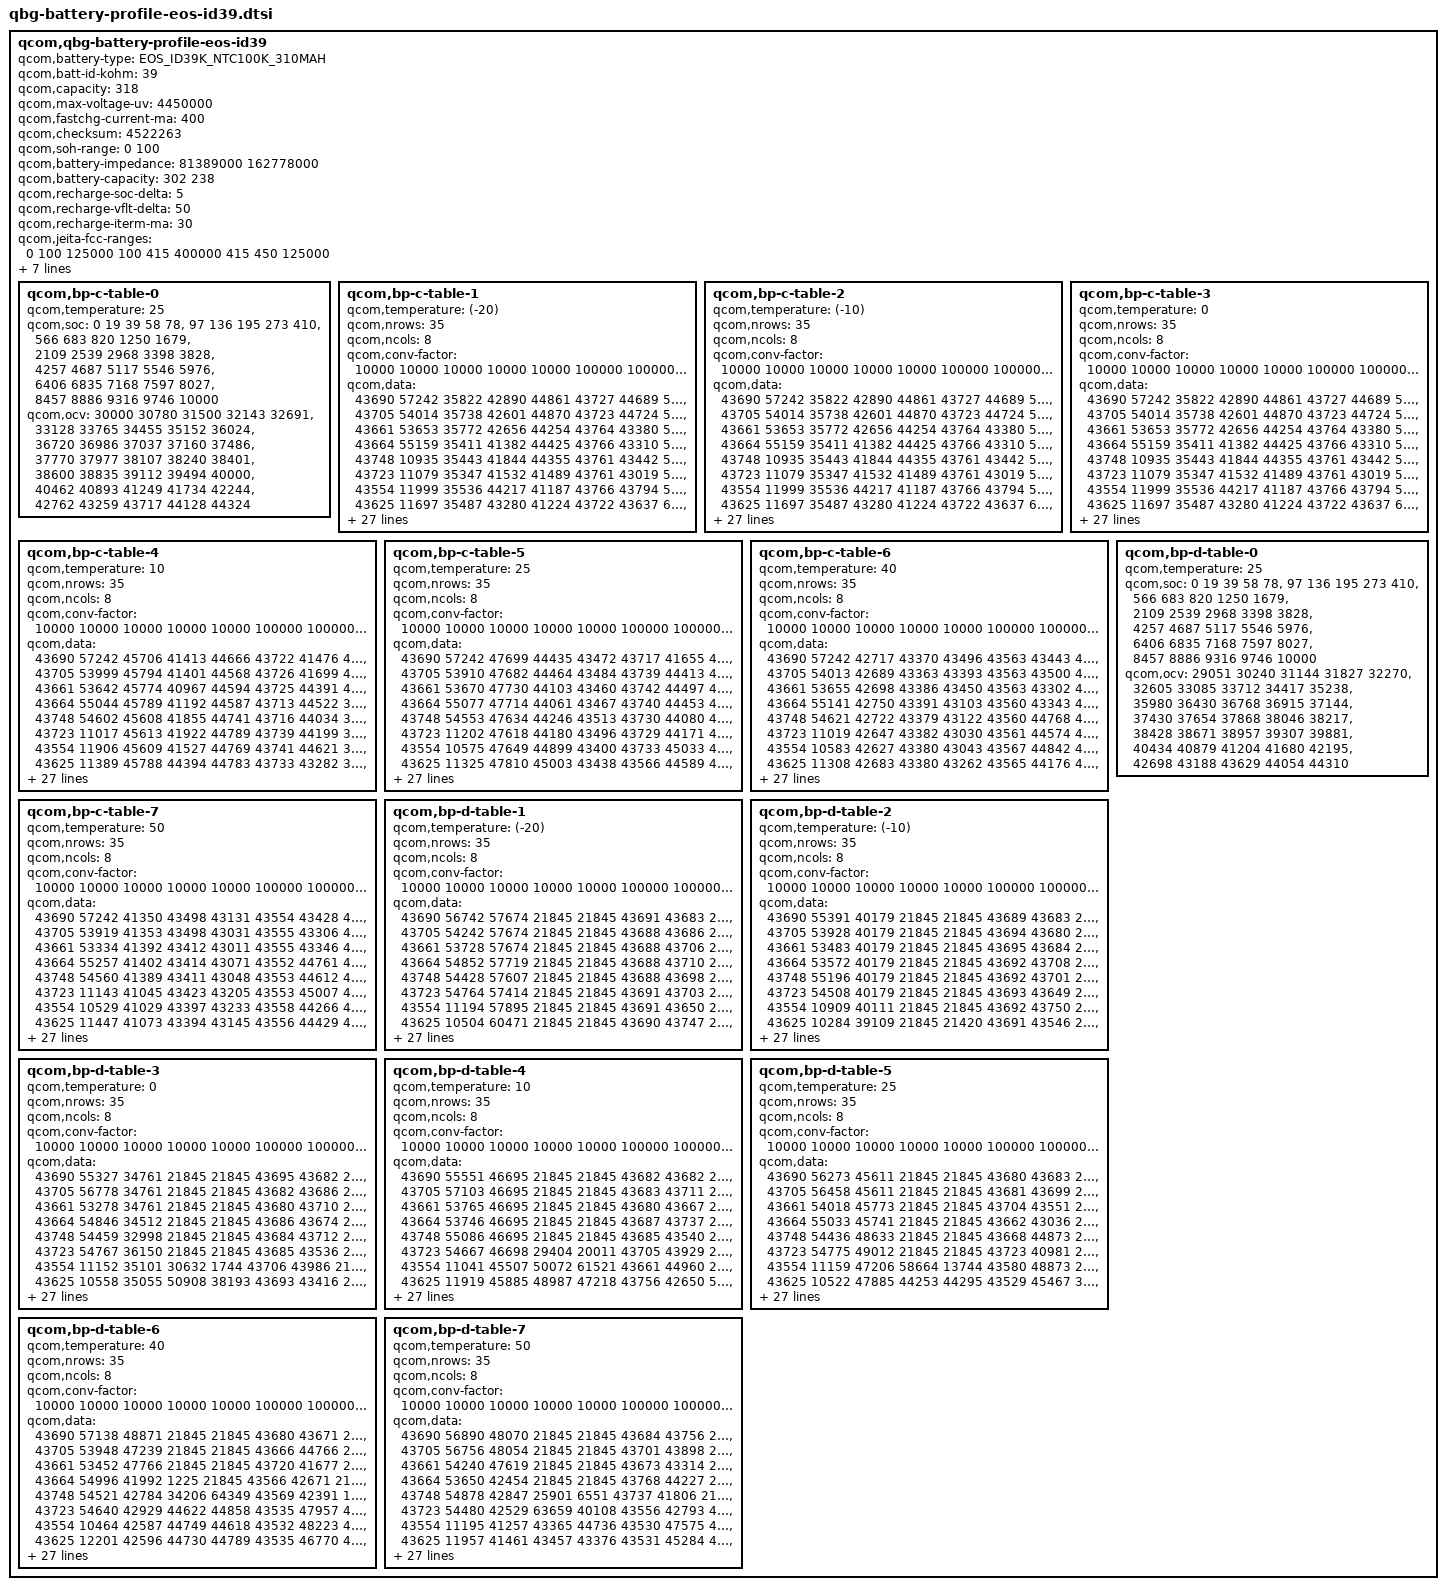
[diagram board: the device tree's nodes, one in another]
// SPDX-License-Identifier: GPL-2.0

/*QBG Profiling Rev. 2.7*/

qcom,qbg-battery-profile-eos-id39 {
	qcom,battery-type = "EOS_ID39K_NTC100K_310MAH";
	qcom,batt-id-kohm = <39>;
	qcom,capacity = <318>;
	qcom,max-voltage-uv = <4450000>;
	qcom,fastchg-current-ma = <400>;
	qcom,checksum = <4522263>; /*@5, 0.005V, 4% */
	qcom,soh-range = <0 100>;
	/*Nominal_Impedance in 10nohm @ SOC 50% 25C* 0:fresh cell, 1: aged cell */
	qcom,battery-impedance = <81389000 162778000>;
	/*Nominal_Capacity in mAh. 0: fresh cell, 1:aged cell*/
	qcom,battery-capacity = <302 238>;
	/*SOC delta (in percent) dropped from EOC SOC to enable recharge*/
	qcom,recharge-soc-delta =<5>;
	/*vfloat delta (in mV) dropped from regular vfloat in recharge*/
	qcom,recharge-vflt-delta =<50>;
	/*termination current (in mA) in recharge*/
	qcom,recharge-iterm-ma = <30>;
	qcom,jeita-fcc-ranges = <0  100 125000
				100 415 400000
				415 450 125000>;

	qcom,jeita-fv-ranges = <0   100 4450000
				100 415 4450000
				415 450 4450000>;

	/* COOL = 10 DegC, WARM = 41 DegC */
	qcom,jeita-soft-thresholds = <0x2b8a 0x14de>;
	/* COLD = 0 DegC, HOT = 45 DegC */
	qcom,jeita-hard-thresholds = <0x3257 0x128c>;
	/* COOL = 12 DegC, WARM = 39 DegC*/
	qcom,jeita-soft-hys-thresholds = <0x2a0b 0x161b>;
	qcom,jeita-soft-fcc-ua = <125000 125000>;
	qcom,jeita-soft-fv-uv = <4450000 4450000>;

	qcom,bp-c-table-0 {
		qcom,temperature = <25>;
		qcom,soc = <    0    19    39    58    78>,
			<   97   136   195   273   410>,
			<  566   683   820  1250  1679>,
			< 2109  2539  2968  3398  3828>,
			< 4257  4687  5117  5546  5976>,
			< 6406  6835  7168  7597  8027>,
			< 8457  8886  9316  9746 10000>;
		qcom,ocv = <30000 30780 31500 32143 32691>,
			<33128 33765 34455 35152 36024>,
			<36720 36986 37037 37160 37486>,
			<37770 37977 38107 38240 38401>,
			<38600 38835 39112 39494 40000>,
			<40462 40893 41249 41734 42244>,
			<42762 43259 43717 44128 44324>;
	};
	qcom,bp-c-table-1 {
		qcom,temperature = <(-20)>;
		qcom,nrows = <35>;
		qcom,ncols = <8>;
		qcom,conv-factor = <10000 10000 10000 10000 10000 100000 100000 10000>;
		qcom,data = <43690 57242 35822 42890 44861 43727 44689 58634>,
			<43705 54014 35738 42601 44870 43723 44724 58378>,
			<43661 53653 35772 42656 44254 43764 43380 59199>,
			<43664 55159 35411 41382 44425 43766 43310 58924>,
			<43748 10935 35443 41844 44355 43761 43442 57820>,
			<43723 11079 35347 41532 41489 43761 43019 57542>,
			<43554 11999 35536 44217 41187 43766 43794 58068>,
			<43625 11697 35487 43280 41224 43722 43637 60655>,
			<43963  9063 46445 43371 41451 43713 43593 60944>,
			<43824 10124 35514 44161 41677 43563 43804 59827>,
			<43164  9597 46437 41588 45038 43553 43464 59567>,
			<43009 14965 46544 44691 41929 43735 43900 59904>,
			<43422 15283 46383 44207 41647 43567 43198 59920>,
			<44616 15112 46550 42720 44909 43729 44228 59762>,
			<44069 14400 46528 42190 44415 43736 44057 60655>,
			<41623 16034 46385 42374 41859 43737 44444 60827>,
			<41793 15949 46531 47790 41927 43739 44484 60830>,
			<41266 16381 46522 47820 41838 43717 44446 60848>,
			<42988 16235 46198 47724 41125 43719 44061 60906>,
			<42078 15509 46147 48035 41005 43719 44890 60700>,
			<47627 15487 46525 48014 41277 43718 45029 57910>,
			<47333 15825 46161 48006 42944 43713 44952 57525>,
			<47447 12937 46163 47280 42461 43715 44436 58976>,
			<48896 13096 46186 47488 42629 43712 41840 57481>,
			<48626 12772 46296 47945 40962 43712 44148 60648>,
			<45996 14262 46281 47714 41800 43712 44722 61140>,
			<45081 13419 46122 48115 41863 43714 44798 61154>,
			<46762 13663 46292 47983 41787 43725 44692 61425>,
			<46855  2821 46129 47492 41564 43739 44790 60450>,
			<46577  2515 46142 47387 41776 43718 44682 58004>,
			<35747  4069 46127 48800 42694 43723 43471 57667>,
			<34844  3475 46093 48721 47666 43722 43117 63935>,
			<36558   904 46570 47454 48342 43727 43159 61470>,
			<36024   127 46588 47283 46409 43714 43893 52995>,
			<36282   339 46130 44517 47008 43593 43541 61736>;
	};
	qcom,bp-c-table-2 {
		qcom,temperature = <(-10)>;
		qcom,nrows = <35>;
		qcom,ncols = <8>;
		qcom,conv-factor = <10000 10000 10000 10000 10000 100000 100000 10000>;
		qcom,data = <43690 57242 35822 42890 44861 43727 44689 58634>,
			<43705 54014 35738 42601 44870 43723 44724 58378>,
			<43661 53653 35772 42656 44254 43764 43380 59199>,
			<43664 55159 35411 41382 44425 43766 43310 58924>,
			<43748 10935 35443 41844 44355 43761 43442 57820>,
			<43723 11079 35347 41532 41489 43761 43019 57542>,
			<43554 11999 35536 44217 41187 43766 43794 58068>,
			<43625 11697 35487 43280 41224 43722 43637 60655>,
			<43963  9063 46445 43371 41451 43713 43593 60944>,
			<43824 10124 35514 44161 41677 43563 43804 59827>,
			<43164  9597 46437 41588 45038 43553 43464 59567>,
			<43009 14965 46544 44691 41929 43735 43900 59904>,
			<43422 15283 46383 44207 41647 43567 43198 59920>,
			<44616 15112 46550 42720 44909 43729 44228 59762>,
			<44069 14400 46528 42190 44415 43736 44057 60655>,
			<41623 16034 46385 42374 41859 43737 44444 60827>,
			<41793 15949 46531 47790 41927 43739 44484 60830>,
			<41266 16381 46522 47820 41838 43717 44446 60848>,
			<42988 16235 46198 47724 41125 43719 44061 60906>,
			<42078 15509 46147 48035 41005 43719 44890 60700>,
			<47627 15487 46525 48014 41277 43718 45029 57910>,
			<47333 15825 46161 48006 42944 43713 44952 57525>,
			<47447 12937 46163 47280 42461 43715 44436 58976>,
			<48896 13096 46186 47488 42629 43712 41840 57481>,
			<48626 12772 46296 47945 40962 43712 44148 60648>,
			<45996 14262 46281 47714 41800 43712 44722 61140>,
			<45081 13419 46122 48115 41863 43714 44798 61154>,
			<46762 13663 46292 47983 41787 43725 44692 61425>,
			<46855  2821 46129 47492 41564 43739 44790 60450>,
			<46577  2515 46142 47387 41776 43718 44682 58004>,
			<35747  4069 46127 48800 42694 43723 43471 57667>,
			<34844  3475 46093 48721 47666 43722 43117 63935>,
			<36558   904 46570 47454 48342 43727 43159 61470>,
			<36024   127 46588 47283 46409 43714 43893 52995>,
			<36282   339 46130 44517 47008 43593 43541 61736>;
	};
	qcom,bp-c-table-3 {
		qcom,temperature = <0>;
		qcom,nrows = <35>;
		qcom,ncols = <8>;
		qcom,conv-factor = <10000 10000 10000 10000 10000 100000 100000 10000>;
		qcom,data = <43690 57242 35822 42890 44861 43727 44689 58634>,
			<43705 54014 35738 42601 44870 43723 44724 58378>,
			<43661 53653 35772 42656 44254 43764 43380 59199>,
			<43664 55159 35411 41382 44425 43766 43310 58924>,
			<43748 10935 35443 41844 44355 43761 43442 57820>,
			<43723 11079 35347 41532 41489 43761 43019 57542>,
			<43554 11999 35536 44217 41187 43766 43794 58068>,
			<43625 11697 35487 43280 41224 43722 43637 60655>,
			<43963  9063 46445 43371 41451 43713 43593 60944>,
			<43824 10124 35514 44161 41677 43563 43804 59827>,
			<43164  9597 46437 41588 45038 43553 43464 59567>,
			<43009 14965 46544 44691 41929 43735 43900 59904>,
			<43422 15283 46383 44207 41647 43567 43198 59920>,
			<44616 15112 46550 42720 44909 43729 44228 59762>,
			<44069 14400 46528 42190 44415 43736 44057 60655>,
			<41623 16034 46385 42374 41859 43737 44444 60827>,
			<41793 15949 46531 47790 41927 43739 44484 60830>,
			<41266 16381 46522 47820 41838 43717 44446 60848>,
			<42988 16235 46198 47724 41125 43719 44061 60906>,
			<42078 15509 46147 48035 41005 43719 44890 60700>,
			<47627 15487 46525 48014 41277 43718 45029 57910>,
			<47333 15825 46161 48006 42944 43713 44952 57525>,
			<47447 12937 46163 47280 42461 43715 44436 58976>,
			<48896 13096 46186 47488 42629 43712 41840 57481>,
			<48626 12772 46296 47945 40962 43712 44148 60648>,
			<45996 14262 46281 47714 41800 43712 44722 61140>,
			<45081 13419 46122 48115 41863 43714 44798 61154>,
			<46762 13663 46292 47983 41787 43725 44692 61425>,
			<46855  2821 46129 47492 41564 43739 44790 60450>,
			<46577  2515 46142 47387 41776 43718 44682 58004>,
			<35747  4069 46127 48800 42694 43723 43471 57667>,
			<34844  3475 46093 48721 47666 43722 43117 63935>,
			<36558   904 46570 47454 48342 43727 43159 61470>,
			<36024   127 46588 47283 46409 43714 43893 52995>,
			<36282   339 46130 44517 47008 43593 43541 61736>;
	};
	qcom,bp-c-table-4 {
		qcom,temperature = <10>;
		qcom,nrows = <35>;
		qcom,ncols = <8>;
		qcom,conv-factor = <10000 10000 10000 10000 10000 100000 100000 10000>;
		qcom,data = <43690 57242 45706 41413 44666 43722 41476 40809>,
			<43705 53999 45794 41401 44568 43726 41699 40533>,
			<43661 53642 45774 40967 44594 43725 44391 40600>,
			<43664 55044 45789 41192 44587 43713 44522 39370>,
			<43748 54602 45608 41855 44741 43716 44034 38948>,
			<43723 11017 45613 41922 44789 43739 44199 39787>,
			<43554 11906 45609 41527 44769 43741 44621 39650>,
			<43625 11389 45788 44394 44783 43733 43282 33805>,
			<43963  9018 45793 44435 44766 43565 43407 34612>,
			<43824  9817 48486 44093 44670 43578 43038 34517>,
			<43164  9479 48436 44080 44604 43579 43396 33046>,
			<43009 14861 48446 44115 43305 43554 44748 32770>,
			<43422 14922 48430 44519 43516 43554 44989 32812>,
			<44616 15304 48581 41489 44819 43561 44996 34603>,
			<44069 14348 48610 41825 44462 43732 44886 33881>,
			<41623 14690 48572 41095 44396 43733 44232 34087>,
			<41793 15886 48211 41087 44303 43728 44528 34094>,
			<41266 16312 48210 41404 44338 43730 44533 34276>,
			<42988 16168 48254 41436 44346 43743 44477 34289>,
			<42078 15527 48159 42658 44288 43742 44235 34051>,
			<47627 15380 48141 41306 41510 43743 44564 39679>,
			<47333 15674 48178 41404 41385 43741 43297 39875>,
			<47447 13021 48169 40986 42930 43742 43269 38985>,
			<48896 13096 48278 42657 42791 43736 44146 40679>,
			<48626 12642 48304 41315 44048 43554 44633 34374>,
			<45996 14130 48299 42625 44970 43571 44939 33033>,
			<45081 13703 48986 41340 44917 43564 44571 33109>,
			<46762  2756 48960 41425 44469 43736 43358 34404>,
			<46855  2193 48960 41339 44342 43738 43313 34670>,
			<46577  3720 48990 42894 44542 43735 43366 34191>,
			<35747  3257 48267 42881 41570 43738 43509 39816>,
			<34844   675 48365 42170 41256 43713 43072 40917>,
			<36558   841 48375 42124 47799 43719 43218 37205>,
			<36024   312 48375 41239 48268 43564 43891 59941>,
			<36282  1751 48277 44361 45880 43640 44011 60162>;
	};
	qcom,bp-c-table-5 {
		qcom,temperature = <25>;
		qcom,nrows = <35>;
		qcom,ncols = <8>;
		qcom,conv-factor = <10000 10000 10000 10000 10000 100000 100000 10000>;
		qcom,data = <43690 57242 47699 44435 43472 43717 41655 46168>,
			<43705 53910 47682 44464 43484 43739 44413 46138>,
			<43661 53670 47730 44103 43460 43742 44497 46222>,
			<43664 55077 47714 44061 43467 43740 44453 46872>,
			<43748 54553 47634 44246 43513 43730 44080 46997>,
			<43723 11202 47618 44180 43496 43729 44171 46695>,
			<43554 10575 47649 44899 43400 43733 45033 45398>,
			<43625 11325 47810 45003 43438 43566 44589 45443>,
			<43963  9210 47843 45037 43102 43554 44754 45078>,
			<43824  9746 47807 44646 43421 43578 43291 45185>,
			<43164  9690 42320 44772 43325 43572 43449 45925>,
			<43009 15056 42352 43365 43434 43581 44731 45607>,
			<43422 14855 42345 44718 43075 43581 44548 45627>,
			<44616 15234 42258 44638 44860 43575 43308 46766>,
			<44069 14532 42450 45003 44916 43574 44769 46639>,
			<41623 14624 42484 44847 44181 43575 44620 46715>,
			<41793 16115 42473 44907 44882 43577 44221 46600>,
			<41266 15985 42379 44921 45030 43557 44253 45387>,
			<42988 16330 42065 44169 44990 43552 44917 45438>,
			<42078 15531 42111 44130 45054 43567 44970 46652>,
			<47627 15458 41990 44438 44212 43564 43388 46869>,
			<47333 15641 42022 44122 44359 43576 43114 46476>,
			<47447 12898 42176 44919 41142 43582 43042 46405>,
			<48896 12524 42210 44811 41775 43556 43265 46164>,
			<48626 14058 42138 44248 44606 43576 44889 45152>,
			<45996 13476 42120 44076 43451 43536 44980 46066>,
			<45081 13591 42166 44133 43469 43544 44546 45907>,
			<46762  2955 42175 44288 43464 43549 45003 45080>,
			<46855  2476 42174 44464 44985 43574 43357 45387>,
			<46577  4014 42120 44351 44816 43569 43472 47086>,
			<35747  3488 42210 41561 45041 43527 44692 46204>,
			<34844   593 42177 41705 41692 43561 43084 35746>,
			<36558   111 42040 41495 41415 43567 43225 36380>,
			<36024  1738 42037 44995 42317 44013 43974 35969>,
			<36282  1934 42211 44561 41240 43563 43889 35754>;
	};
	qcom,bp-c-table-6 {
		qcom,temperature = <40>;
		qcom,nrows = <35>;
		qcom,ncols = <8>;
		qcom,conv-factor = <10000 10000 10000 10000 10000 100000 100000 10000>;
		qcom,data = <43690 57242 42717 43370 43496 43563 43443 48721>,
			<43705 54013 42689 43363 43393 43563 43500 48740>,
			<43661 53655 42698 43386 43450 43563 43302 48651>,
			<43664 55141 42750 43391 43103 43560 43343 48862>,
			<43748 54621 42722 43379 43122 43560 44768 48866>,
			<43723 11019 42647 43382 43030 43561 44574 48820>,
			<43554 10583 42627 43380 43043 43567 44842 47482>,
			<43625 11308 42683 43380 43262 43565 44176 47580>,
			<43963  9088 41302 43385 43160 43552 44085 47488>,
			<43824  9940 41289 43369 43150 43556 44094 47178>,
			<43164  9613 41339 43298 43242 43570 44842 47114>,
			<43009 14999 41312 43221 43255 43544 44551 47911>,
			<43422 15045 41321 43041 43253 43524 44971 47933>,
			<44616 14921 41244 43418 44551 43527 43085 48688>,
			<44069 14478 41224 43414 44603 43545 43309 48849>,
			<41623 14739 41278 43461 44645 43539 44734 48766>,
			<41793 16057 41260 43410 44654 43525 44700 48674>,
			<41266 15888 41414 43429 43329 43573 44580 47405>,
			<42988 16379 41464 43485 43278 43570 44553 47418>,
			<42078 15528 41360 43332 44706 43583 43364 48832>,
			<47627 15481 41397 44791 44561 43581 43446 48935>,
			<47333 15726 41378 44637 44846 43573 43087 48213>,
			<47447 12870 41048 44682 44521 43544 43234 48431>,
			<48896 12323 41073 43459 44080 43521 43099 48261>,
			<48626 14041 41056 43445 43333 43574 43370 47174>,
			<45996 13462 40981 43112 43511 43574 43132 47955>,
			<45081 13662 40991 43398 43279 43575 43085 47134>,
			<46762  3019 40965 44969 43055 43598 44267 47570>,
			<46855  2552 40964 44697 44788 43526 43320 48856>,
			<46577  4089 40986 45054 44731 43643 44789 48942>,
			<35747  3568 40976 44175 43329 43588 44668 48174>,
			<34844  1007 41061 44194 44959 43641 43390 48441>,
			<36558    85 41079 45043 44337 43551 43082 45956>,
			<36024  1568 41074 43266 44294 44017 43144 48391>,
			<36282  2045 41194 43009 41568 43568 43798 48222>;
	};
	qcom,bp-c-table-7 {
		qcom,temperature = <50>;
		qcom,nrows = <35>;
		qcom,ncols = <8>;
		qcom,conv-factor = <10000 10000 10000 10000 10000 100000 100000 10000>;
		qcom,data = <43690 57242 41350 43498 43131 43554 43428 47155>,
			<43705 53919 41353 43498 43031 43555 43306 47320>,
			<43661 53334 41392 43412 43011 43555 43346 47329>,
			<43664 55257 41402 43414 43071 43552 44761 47247>,
			<43748 54560 41389 43411 43048 43553 44612 47957>,
			<43723 11143 41045 43423 43205 43553 45007 47985>,
			<43554 10529 41029 43397 43233 43558 44266 47923>,
			<43625 11447 41073 43394 43145 43556 44429 48097>,
			<43963  8815 41069 43402 43178 43578 44399 48044>,
			<43824  9911 40989 43444 43851 43583 41717 47723>,
			<43164  9325 40975 43448 43900 43571 41654 47649>,
			<43009  9556 41015 43840 43149 43630 43345 42285>,
			<43422 15005 41011 43865 43191 43541 44617 42287>,
			<44616 14862 41019 43253 44705 43536 43071 47960>,
			<44069 15220 41007 43134 43327 43548 44721 47948>,
			<41623 14423 41171 43071 44709 43537 43269 47265>,
			<41793 14709 41155 43048 44706 43538 43350 47936>,
			<41266 15927 41213 43248 43464 43547 44740 48058>,
			<42988 16366 41198 43049 43429 43534 44689 47732>,
			<42078 16209 41092 43132 43310 43569 43495 47876>,
			<47627 15461 41149 43304 43358 43568 43408 47215>,
			<47333 15712 41132 43265 44640 43530 43015 47476>,
			<47447 12884 41817 43409 44201 43525 43196 48877>,
			<48896 12298 41803 43226 45020 43545 43253 47520>,
			<48626 13866 41848 43242 43512 43525 43476 47808>,
			<45996 13551 41836 43208 43055 43520 43339 42258>,
			<45081  2731 41747 43231 43444 43522 43441 47818>,
			<46762  3038 41755 43064 43316 43533 43129 47709>,
			<46855  2511 41728 43318 43510 43643 44749 47986>,
			<46577  4034 41730 43376 43388 43647 44710 47114>,
			<35747  3533 41729 44798 44699 43594 44691 47405>,
			<34844   999 41759 44762 44641 43621 44721 48841>,
			<36558   431 41747 44689 44074 43630 43443 49001>,
			<36024  1571 41752 43489 45034 43606 43490 47412>,
			<36282  1992 41556 43196 41680 43533 43800 48667>;
	};
	qcom,bp-d-table-0 {
		qcom,temperature = <25>;
		qcom,soc = <    0    19    39    58    78>,
			<   97   136   195   273   410>,
			<  566   683   820  1250  1679>,
			< 2109  2539  2968  3398  3828>,
			< 4257  4687  5117  5546  5976>,
			< 6406  6835  7168  7597  8027>,
			< 8457  8886  9316  9746 10000>;
		qcom,ocv = <29051 30240 31144 31827 32270>,
			<32605 33085 33712 34417 35238>,
			<35980 36430 36768 36915 37144>,
			<37430 37654 37868 38046 38217>,
			<38428 38671 38957 39307 39881>,
			<40434 40879 41204 41680 42195>,
			<42698 43188 43629 44054 44310>;
	};
	qcom,bp-d-table-1 {
		qcom,temperature = <(-20)>;
		qcom,nrows = <35>;
		qcom,ncols = <8>;
		qcom,conv-factor = <10000 10000 10000 10000 10000 100000 100000 10000>;
		qcom,data = <43690 56742 57674 21845 21845 43691 43683 21845>,
			<43705 54242 57674 21845 21845 43688 43686 21845>,
			<43661 53728 57674 21845 21845 43688 43706 21845>,
			<43664 54852 57719 21845 21845 43688 43710 21845>,
			<43748 54428 57607 21845 21845 43688 43698 21845>,
			<43723 54764 57414 21845 21845 43691 43703 21845>,
			<43554 11194 57895 21845 21845 43691 43650 21845>,
			<43625 10504 60471 21845 21845 43690 43747 21845>,
			<43963 11279 61406 21845 32405 43690 43553 21845>,
			<43824  8429 59669 21845 62057 43690 43595 21845>,
			<43164  9822 59908 21845 40702 43690 44015 21845>,
			<43009  9357 38340 21576 33691 43690 43812 21845>,
			<43422  9644 38105 27066 35455 43691 43844 21845>,
			<44616 15068 37224 12515 33504 43691 43186 21845>,
			<44069 15351 37364 53391 33682 43691 43173 21845>,
			<41623 14498 37055 51207 36596 43688 43147 21845>,
			<41793 14384 37389 64167 46880 43688 43233 21845>,
			<41266 14725 39956 59704 45687 43689 43202 21763>,
			<42988 14715 40374 37641 48981 43689 43209 17260>,
			<42078 16087 40798 39780 47462 43689 43249 32110>,
			<47627 16275 40565 33127 47990 43694 43210 25341>,
			<47333 15534 40486 36155 42310 43694 43045  4483>,
			<47447 15476 39267 36412 42837 43695 43079  1297>,
			<48896 15715 39375 35687 42549 43692 43498  4043>,
			<48626 12903 39767 46362 41396 43693 43335 13922>,
			<45996 12463 39769 46482 41953 43693 45014 16203>,
			<45081 12572 39918 46097 41880 43682 44361 15251>,
			<46762 14329 39492 46130 41940 43683 41200  9501>,
			<46855 13589 39505 46182 41075 43683 42170  9286>,
			<46577  2244 39447 46188 42595 43680 47737  9301>,
			<35747  2390 39811 46631 42583 43681 41130  8294>,
			<34844  3230 39487 46990 42566 43686 41827  8611>,
			<36558   537 34138 47096 41325 43684 41871  9174>,
			<36024   465 34198 47098 41903 43706 44333 11862>,
			<36282  2023 34290 46996 41655 43707 44144 10627>;
	};
	qcom,bp-d-table-2 {
		qcom,temperature = <(-10)>;
		qcom,nrows = <35>;
		qcom,ncols = <8>;
		qcom,conv-factor = <10000 10000 10000 10000 10000 100000 100000 10000>;
		qcom,data = <43690 55391 40179 21845 21845 43689 43683 21845>,
			<43705 53928 40179 21845 21845 43694 43680 21845>,
			<43661 53483 40179 21845 21845 43695 43684 21845>,
			<43664 53572 40179 21845 21845 43692 43708 21845>,
			<43748 55196 40179 21845 21845 43692 43701 21845>,
			<43723 54508 40179 21845 21845 43693 43649 21845>,
			<43554 10909 40111 21845 21845 43692 43750 21845>,
			<43625 10284 39109 21845 21420 43691 43546 21845>,
			<43963 12249 39616 21845 64351 43690 44011 21845>,
			<43824  8971 34248  9463 47034 43691 43170 21845>,
			<43164 10146 34710 64152 47789 43691 43429 21845>,
			<43009  9219 34472 37221 42763 43688 43329 19640>,
			<43422  9534 33081 34812 41340 43688 44688 28454>,
			<44616 14975 33603 34734 42100 43689 43321  4128>,
			<44069 15112 33381 33718 47625 43694 43121  2007>,
			<41623 14481 36129 34865 42493 43695 43009 12766>,
			<41793 14357 36314 46813 42512 43692 43117  8231>,
			<41266 14826 36281 48468 41214 43682 43441 54803>,
			<42988 14689 35996 48648 44375 43681 43352 55849>,
			<42078 16066 36687 47893 44067 43684 44643 52370>,
			<47627 16310 36626 42332 44848 43705 44875 62935>,
			<47333 16218 36841 42373 44985 43697 44532 61769>,
			<47447 15443 36418 42102 44612 43662 41592 61586>,
			<48896 13023 36477 42372 44764 43714 47276 61633>,
			<48626 12452 36472 42468 45052 43716 48125 61871>,
			<45996 12652 36466 42360 44216 43742 47992 61753>,
			<45081 13563 36453 47681 41616 43734 47458 62607>,
			<46762 13639 36367 48017 41905 43729 47121 62892>,
			<46855  3067 36595 48111 41908 43717 41057 62611>,
			<46577  2415 36405 48809 41490 43730 48043 51769>,
			<35747  3946 36604 48666 41934 43725 42843 52194>,
			<34844  3357 35158 49145 41745 43764 41426 51452>,
			<36558   783 35093 48935 41592 43769 41949 51985>,
			<36024   379 35125 48930 44210 43756 44411 62528>,
			<36282  2023 35085 49148 44624 43668 44425 62999>;
	};
	qcom,bp-d-table-3 {
		qcom,temperature = <0>;
		qcom,nrows = <35>;
		qcom,ncols = <8>;
		qcom,conv-factor = <10000 10000 10000 10000 10000 100000 100000 10000>;
		qcom,data = <43690 55327 34761 21845 21845 43695 43682 21845>,
			<43705 56778 34761 21845 21845 43682 43686 21845>,
			<43661 53278 34761 21845 21845 43680 43710 21845>,
			<43664 54846 34512 21845 21845 43686 43674 21845>,
			<43748 54459 32998 21845 21845 43684 43712 21845>,
			<43723 54767 36150 21845 21845 43685 43536 21845>,
			<43554 11152 35101 30632  1744 43706 43986 21845>,
			<43625 10558 35055 50908 38193 43693 43416 21845>,
			<43963 11444 35629 38651 45630 43688 44961 19113>,
			<43824  9058 35397 35111 41017 43689 45016  3838>,
			<43164 10168 46424 49047 44258 43694 44077 54970>,
			<43009  9324 46542 47719 45016 43692 44299 50844>,
			<43422  9495 46166 42955 44562 43683 41658 51950>,
			<44616 14903 46160 47731 45035 43680 44917 51498>,
			<44069 15357 46954 42178 43385 43706 44356 64802>,
			<41623 14546 47093 42516 43388 43755 48663 64368>,
			<41793 14843 46623 41332 44683 43713 48573 58545>,
			<41266 14596 46598 41393 43336 43736 47274 58143>,
			<42988 16034 46633 41108 43295 43743 41328 61247>,
			<42078 15931 46734 41128 43311 43741 41067 59448>,
			<47627 16325 45379 41093 43468 43735 42842 60393>,
			<47333 15421 45382 40990 43477 43560 47509 59986>,
			<47447 15713 46741 41063 44686 43560 47623 59998>,
			<48896 13192 46720 41377 44574 43560 42854 60329>,
			<48626 12297 46740 41256 44936 43560 41292 60402>,
			<45996 13944 45387 42600 44276 43560 42418 59818>,
			<45081 13417 45329 42815 44416 43732 42747 59679>,
			<46762  2799 45338 42188 44485 43730 41061 61178>,
			<46855  2258 45357 47794 44318 43739 42885 60564>,
			<46577  3834 45512 47656 41672 43722 41981 60814>,
			<35747  3220 45554 48031 41527 43763 44361 58092>,
			<34844   656 45563 47324 41686 43774 41606 57525>,
			<36558   163 45447 47591 44484 43751 41617 57563>,
			<36024   351 45173 47419 44963 43754 44405 58320>,
			<36282  1939 45166 47584 44708 43666 44493 60764>;
	};
	qcom,bp-d-table-4 {
		qcom,temperature = <10>;
		qcom,nrows = <35>;
		qcom,ncols = <8>;
		qcom,conv-factor = <10000 10000 10000 10000 10000 100000 100000 10000>;
		qcom,data = <43690 55551 46695 21845 21845 43682 43682 21845>,
			<43705 57103 46695 21845 21845 43683 43711 21845>,
			<43661 53765 46695 21845 21845 43680 43667 21845>,
			<43664 53746 46695 21845 21845 43687 43737 21845>,
			<43748 55086 46695 21845 21845 43685 43540 21845>,
			<43723 54667 46698 29404 20011 43705 43929 21845>,
			<43554 11041 45507 50072 61521 43661 44960 21845>,
			<43625 11919 45885 48987 47218 43756 42650 56811>,
			<43963 11277 46054 42237 41855 43760 47159 51353>,
			<43824  9031 45691 41055 44755 43745 48705 64494>,
			<43164  9793 45718 44482 43430 43764 42950 59683>,
			<43009  9222 45758 44106 43420 43718 41277 60111>,
			<43422  9496 48467 44093 43442 43580 41014 38765>,
			<44616 15090 48491 41624 43068 43719 41836 60022>,
			<44069 15347 48565 41718 43120 43717 42928 38676>,
			<41623 14557 48210 44382 44708 43731 41414 37844>,
			<41793 14729 48154 44348 44679 43567 41101 40934>,
			<41266 14645 48190 44347 43360 43559 41013 39055>,
			<42988 16020 48340 44387 43462 43577 42143 39477>,
			<42078 16293 48323 44378 43487 43577 47853 34151>,
			<47627 16216 48370 44363 43287 43579 42097 33875>,
			<47333 15476 48362 44394 43329 43556 41036 33970>,
			<47447 12969 48296 44373 44735 43559 41839 34662>,
			<48896 13301 48308 41510 44768 43555 41956 34652>,
			<48626 12715 48295 41976 44553 43561 41728 34007>,
			<45996 14312 48994 40977 44803 43566 42994 39662>,
			<45081 13778 48902 42734 44190 43560 42409 39769>,
			<46762  2654 48909 42508 44071 43728 42782 38971>,
			<46855  2079 48945 42719 44433 43725 44408 38977>,
			<46577  3595 48905 42582 44437 43726 44078 39216>,
			<35747  3125 48934 42869 44052 43720 44134 40673>,
			<34844   575 49094 42195 44233 43765 44419 40557>,
			<36558   248 49102 42185 44846 43762 44288 40604>,
			<36024  1726 49105 42762 43390 43749 41704 39047>,
			<36282  1950 48948 42617 43101 43747 41480 39488>;
	};
	qcom,bp-d-table-5 {
		qcom,temperature = <25>;
		qcom,nrows = <35>;
		qcom,ncols = <8>;
		qcom,conv-factor = <10000 10000 10000 10000 10000 100000 100000 10000>;
		qcom,data = <43690 56273 45611 21845 21845 43680 43683 21845>,
			<43705 56458 45611 21845 21845 43681 43699 21845>,
			<43661 54018 45773 21845 21845 43704 43551 21845>,
			<43664 55033 45741 21845 21845 43662 43036 21845>,
			<43748 54436 48633 21845 21845 43668 44873 21845>,
			<43723 54775 49012 21845 21845 43723 40981 21845>,
			<43554 11159 47206 58664 13744 43580 48873 21845>,
			<43625 10522 47885 44253 44295 43529 45467 36770>,
			<43963 11483 48066 44858 44890 43529 46334 35802>,
			<43824  8972 48004 44934 43321 43523 35369 46208>,
			<43164  9766 48059 44625 43186 43545 46897 46723>,
			<43009  9444 47689 44568 43855 43547 47668 45550>,
			<43422  9482 47638 44671 43152 43524 41134 45508>,
			<44616 15001 47720 44741 43831 43572 41811 45293>,
			<44069 15282 47653 44595 43203 43579 41593 45491>,
			<41623 14492 47757 44654 43446 43526 41668 45157>,
			<41793 14780 42328 44632 43477 43524 41873 45159>,
			<41266 14662 42257 44928 43386 43549 41377 45133>,
			<42988 15924 42274 44630 44733 43547 41732 45061>,
			<42078 16355 42494 44652 44704 43521 44300 45889>,
			<47627 15542 42419 44629 43510 43551 41617 46056>,
			<47333 15781 42075 44988 43124 43525 41498 45631>,
			<47447 12935 42095 44630 43034 43528 41623 45744>,
			<48896 13089 41997 44934 43070 43528 41942 45755>,
			<48626 12643 42198 44251 43464 43551 45333 45911>,
			<45996 14168 42189 44082 44651 43520 48137 45358>,
			<45081 13573 42224 44238 44964 43580 42542 45351>,
			<46762  2654 42239 44208 44990 43558 41714 45554>,
			<46855  2170 42239 44914 44950 43564 44801 45537>,
			<46577  3705 42178 44161 44666 43557 45037 45514>,
			<35747  3168 42200 44434 43460 43583 44454 45471>,
			<34844   542 42017 44538 43123 43556 44358 45151>,
			<36558   199 41985 44107 43065 43554 41533 45262>,
			<36024  1724 42084 44912 43203 43565 41966 46028>,
			<36282  1980 42058 45032 43204 43558 41880 45668>;
	};
	qcom,bp-d-table-6 {
		qcom,temperature = <40>;
		qcom,nrows = <35>;
		qcom,ncols = <8>;
		qcom,conv-factor = <10000 10000 10000 10000 10000 100000 100000 10000>;
		qcom,data = <43690 57138 48871 21845 21845 43680 43671 21845>,
			<43705 53948 47239 21845 21845 43666 44766 21845>,
			<43661 53452 47766 21845 21845 43720 41677 21845>,
			<43664 54996 41992  1225 21845 43566 42671 21845>,
			<43748 54521 42784 34206 64349 43569 42391 14448>,
			<43723 54640 42929 44622 44858 43535 47957 46043>,
			<43554 10464 42587 44749 44618 43532 48223 48456>,
			<43625 12201 42596 44730 44789 43535 46770 48149>,
			<43963 11556 42511 43361 43335 43534 46168 49003>,
			<43824  8225 42704 43290 43063 43521 35779 48803>,
			<43164 10119 42742 43296 43983 43550 46397 47323>,
			<43009  9236 42725 43314 44015 43524 47853 47353>,
			<43422  9501 42721 43350 43822 43527 41394 47197>,
			<44616 15033 42646 43496 43923 43553 41161 47938>,
			<44069 15264 42663 43396 43870 43545 41741 47341>,
			<41623 14525 41329 43466 43213 43630 44410 47123>,
			<41793 14757 41322 43473 43133 43619 41866 47540>,
			<41266 14685 41225 43456 43299 43632 41610 47368>,
			<42988 15878 41262 43295 43412 43945 41688 47392>,
			<42078 16368 41422 43356 43070 43936 41881 47546>,
			<47627 15493 41455 43352 43247 43584 41756 47160>,
			<47333 15751 41344 43365 43861 43640 41071 47268>,
			<47447 13027 41400 43310 43874 43631 40972 48089>,
			<48896 13109 41047 43492 43901 43540 41193 48027>,
			<48626 12625 41030 43342 43305 43624 49080 47575>,
			<45996 14198 41076 43284 44764 43546 42053 48820>,
			<45081 13778 41084 43490 44600 43581 44342 47433>,
			<46762  2657 41081 43401 44578 43577 44828 47374>,
			<46855  2064 41080 43507 44678 43533 45039 47416>,
			<46577  3637 41074 44566 43159 43633 41532 47495>,
			<35747  3133 41077 44636 43816 43538 41008 47215>,
			<34844   557 41033 44594 43968 43574 41349 47340>,
			<36558   236 41029 43356 43973 43569 41380 47902>,
			<36024   325 41389 43417 43814 43524 41113 48058>,
			<36282  1603 41401 43038 43779 43623 41970 47618>;
	};
	qcom,bp-d-table-7 {
		qcom,temperature = <50>;
		qcom,nrows = <35>;
		qcom,ncols = <8>;
		qcom,conv-factor = <10000 10000 10000 10000 10000 100000 100000 10000>;
		qcom,data = <43690 56890 48070 21845 21845 43684 43756 21845>,
			<43705 56756 48054 21845 21845 43701 43898 21845>,
			<43661 54240 47619 21845 21845 43673 43314 21845>,
			<43664 53650 42454 21845 21845 43768 44227 21845>,
			<43748 54878 42847 25901  6551 43737 41806 21845>,
			<43723 54480 42529 63659 40108 43556 42793 49923>,
			<43554 11195 41257 43365 44736 43530 47575 49054>,
			<43625 11957 41461 43457 43376 43531 45284 48811>,
			<43963 11359 41361 43399 43321 43569 46326 47594>,
			<43824  8332 41407 43426 43039 43572 35669 47959>,
			<43164  9835 41047 43433 43830 43532 35828 47645>,
			<43009  9446 41029 43083 43906 43530 48101 47788>,
			<43422  9683 41024 43457 44016 43531 41331 47714>,
			<44616  9550 41084 43037 43585 43583 42877 42302>,
			<44069 14945 40990 43070 43791 43543 41953 42359>,
			<41623 15176 41010 43438 43873 43636 41174 47817>,
			<41793 14451 41001 43112 43236 43598 41973 47655>,
			<41266 14692 41159 43091 43008 43930 41583 48060>,
			<42988 15879 41213 43273 43225 43926 42727 48065>,
			<42078 16351 41195 43286 43235 43941 42924 48125>,
			<47627 15598 41089 43518 43257 43587 41970 47714>,
			<47333 15763 41151 43413 43874 43636 41214 47793>,
			<47447 13050 41130 43096 43972 43646 41396 42441>,
			<48896 13063 41818 43012 43811 43628 42660 42368>,
			<48626 12632 41844 43079 43488 43630 47698 48029>,
			<45996 14109 41851 43017 44722 43527 41401 48086>,
			<45081 13771 41827 43256 44699 43532 44880 48079>,
			<46762  2671 41839 43238 44687 43520 45026 48110>,
			<46855  2052 41833 43085 43493 43623 44822 48008>,
			<46577  3621 41832 44788 43924 43611 42620 47630>,
			<35747  3104 41839 43355 44010 43524 41209 47761>,
			<34844   720 41824 43465 44011 43578 41140 42258>,
			<36558   146 41852 43123 44014 43583 41121 42394>,
			<36024   372 41795 43249 44002 43543 41804 41984>,
			<36282  1663 41822 43198 44006 43586 41837 42225>;
	};
};
